AUTOSAR XML (schema 4-2-2)
package /ComponentTypes
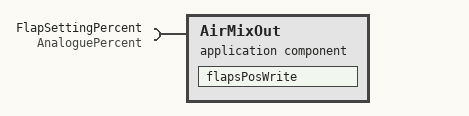
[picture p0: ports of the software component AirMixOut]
  application sw component type AirMixOut
    require port FlapSettingPercent: nonqueued-receiver-com-spec{data-element=flapSettingPercent, init-value=0}, required-interface=AnaloguePercent
    behavior AirMixOut_InternalBehavior: data-type-mapping=flapMapSet
      data received event DRT_flapsPosWrite_FlapSettingPercent_flapSettingPercent: start-on-event=flapsPosWrite, data=FlapSettingPercent.flapSettingPercent
      runnable flapsPosWrite
        data-receive-point-by-arguments:
          access REC_FlapSettingPercent_flapSettingPercent: accessed-variable=FlapSettingPercent.flapSettingPercent
  swc implementation AirMixOut_Implementation: behavior=AirMixOut_InternalBehavior
